# WKUP_PRM register map
Vendor: Texas Instruments
Peripheral module from a debugger description file (folder omap36xx).
Registers are 32-bit, access per field, reset 0x0 unless marked. A register's access mark holds for its fields unless they carry their own. Offsets are as the file gives them; lines under a group give offsets from that group; [hi:lo] are bit positions; {n}, {i} and the like mark numbered series; 'fields as' and 'values as' point back to an identical list; <NAME> marks a mode.

## WKUP_PRM
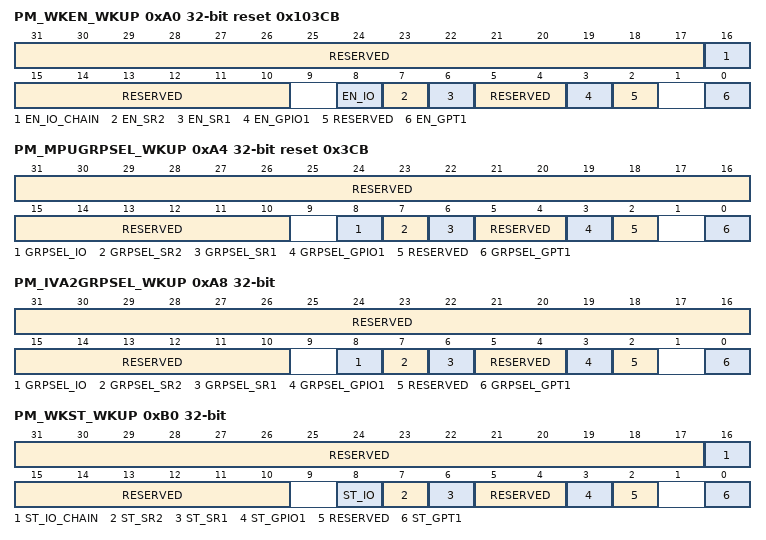
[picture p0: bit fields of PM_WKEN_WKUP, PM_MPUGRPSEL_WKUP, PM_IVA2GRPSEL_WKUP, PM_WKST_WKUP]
0xA0 PM_WKEN_WKUP reset 0x103CB — This register allows enabling/disabling modules wake-up events.
  [31:17] RESERVED ro — Write 0s for future compatibility. Read returns 0.
  [16] EN_IO_CHAIN rw — I/O daisy chain wakeup is disabled.
    0=I/O wake-up daisy chain is disabled; 1=I/O wake-up daisy chain event is enabled
  [15:10] RESERVED ro — Write 0s for future compatibility. Read returns 0.
  [8] EN_IO rw — IO pad wake-up control
    0=IO pad wakeup is disabled; 1=IO pad wake-up event is enabled
  [7] EN_SR2 rw — SmartRefex 2 wake-up control
    0=SmartReflex 2 wakeup is disabled; 1=Smart Reflex 2 wake-up event is enabled
  [6] EN_SR1 rw — Smart Refex 1 wakeup control
    0=SmartReflex 1 wakeup is disabled; 1=SmartReflex 1 wake-up event is enabled
  [5:4] RESERVED ro — Write 0s for future compatibility. Read returns 0.
  [3] EN_GPIO1 rw — GPIO 1 wake-up control
    0=GPIO 1 wakeup is disabled; 1=GPIO 1 wake-up event is enabled
  [2] RESERVED ro — Write 0s for future compatibility. Read returns 0.
  [0] EN_GPT1 rw — GPTIMER 1 wake-up control
    0=GPTIMER 1 wakeup is disabled; 1=GPTIMER 1 wake-up event is enabled
0xA4 PM_MPUGRPSEL_WKUP reset 0x3CB — IO pad is always selected in the MPU wake-up events group
  [31:10] RESERVED ro — Write 0s for future compatibility. Read returns 0.
  [8] GRPSEL_IO ro — IO pad is always selected in the MPU wake-up events group
  [7] GRPSEL_SR2 rw — Select the Smart Reflex 2 in the MPU wake-up events group
    0=Smart Reflex 2 is not attached to the MPU wake-up events group; 1=Smart Reflex 2 is attached to the MPU wake-up events group
  [6] GRPSEL_SR1 rw — Select the Smart Reflex 1 in the MPU wake-up events group
    0=Smart Reflex 1 is not attached to the MPU wake-up events group; 1=Smart Reflex 1 is attached to the MPU wake-up events group
  [5:4] RESERVED ro — Write 0s for future compatibility. Read returns 0.
  [3] GRPSEL_GPIO1 rw — Select the GPIO 1 in the MPU wake-up events group
    0=GPIO 1 is not attached to the MPU wake-up events group; 1=GPIO 1 is attached to the MPU wake-up events group
  [2] RESERVED ro — Write 0s for future compatibility. Read returns 0.
  [0] GRPSEL_GPT1 rw — Select the GPTIMER 1 in the MPU wake-up events group
    0=GPTIMER 1 is not attached to the MPU wake-up events group; 1=GPTIMER 1 is attached to the MPU wake-up events group
0xA8 PM_IVA2GRPSEL_WKUP — This register allows selecting the group of modules that wake-up the IVA2.
  [31:10] RESERVED ro — Write 0s for future compatibility. Read returns 0.
  [8] GRPSEL_IO rw — Select the IO pad in the IVA2 wake-up events group
    0=IO pad module is not attached to the IVA2 wake-up events group; 1=IO pad module is attached to the IVA2 wake-up events group
  [7] GRPSEL_SR2 rw — Select the Smart Reflex 2 in the IVA2 wake-up events group
    0=Smart Reflex 2 is not attached to the IVA2 wake-up events group; 1=Smart Reflex 2 is attached to the IVA2 wake-up events group
  [6] GRPSEL_SR1 rw — Select the Smart Reflex 1 in the IVA2 wake-up events group
    0=Smart Reflex 1 is not attached to the IVA2 wake-up events group; 1=Smart Reflex 1 is attached to the IVA2 wake-up events group
  [5:4] RESERVED ro — Write 0s for future compatibility. Read returns 0.
  [3] GRPSEL_GPIO1 rw — Select the GPIO 1 in the IVA2 wake-up events group
    0=GPIO 1 is not attached to the IVA2 wake-up events group; 1=GPIO 1 is attached to the IVA2 wake-up events group
  [2] RESERVED ro — Write 0s for future compatibility. Read returns 0.
  [0] GRPSEL_GPT1 rw — Select the GPTIMER 1 in the IVA2 wake-up events group
    0=GPTIMER 1 is not attached to the IVA2 wake-up events group; 1=GPTIMER 1 is attached to the IVA2 wake-up events group
0xB0 PM_WKST_WKUP — This register logs module wake-up events. Must be cleared by software. If it is not cleared, it prevents further domain transition.
  [31:17] RESERVED ro — Write 0s for future compatibility. Read returns 0.
  [16] ST_IO_CHAIN rw — I/O wake-up scheme completion status.
    0=ST_IO_CHAIN_0_r (The I/O wake-up scheme is not enabled or is not complete.); 0=ST_IO_CHAIN_0_w (The status bit is unchanged.); 1=ST_IO_CHAIN_1_r (The I/O wake-up scheme is enabled.); 1=ST_IO_CHAIN_1_w (The status bit is cleared to 0.)
  [15:10] RESERVED ro — Write 0s for future compatibility. Read returns 0.
  [8] ST_IO rw — IO pad wake-up status
    0=ST_IO_0_r (IO pad wakeup did not occur or was masked.); 0=ST_IO_0_w (Status bit unchanged); 1=ST_IO_1_r (IO pad wakeup occurred.); 1=ST_IO_1_w (Status bit is cleared to 0.)
  [7] ST_SR2 rw — Smart Reflex 2 wake-up status
    0=ST_SR2_0_r (Smart Reflex 2 wakeup did not occur or was masked.); 0=ST_SR2_0_w (Status bit unchanged); 1=ST_SR2_1_r (Smart Reflex 2 wakeup occurred.); 1=ST_SR2_1_w (Status bit is cleared to 0.)
  [6] ST_SR1 rw — Smart Reflex 1 wake-up status
    0=ST_SR1_0_r (Smart Reflex 1 wakeup did not occur or was masked.); 0=ST_SR1_0_w (Status bit unchanged); 1=ST_SR1_1_r (Smart Reflex 1 wakeup occurred.); 1=ST_SR1_1_w (Status bit is cleared to 0.)
  [5:4] RESERVED ro — Write 0s for future compatibility. Read returns 0.
  [3] ST_GPIO1 rw — GPIO 1 Wake-up status
    0=ST_GPIO1_0_r (GPIO 1 wakeup did not occur or was masked.); 0=ST_GPIO1_0_w (Status bit unchanged); 1=ST_GPIO1_1_r (GPIO 1 wakeup occurred.); 1=ST_GPIO1_1_w (Status bit is cleared to 0.)
  [2] RESERVED ro — Write 0s for future compatibility. Read returns 0.
  [0] ST_GPT1 rw — GPTIMER 1 wake-up status
    0=ST_GPT1_0_r (GPTIMER 1 wakeup did not occur or was masked.); 0=ST_GPT1_0_w (Status bit unchanged); 1=ST_GPT1_1_r (GPTIMER 1 wakeup occurred.); 1=ST_GPT1_1_w (Status bit is cleared to 0.)
